AUTOSAR XML (schema 4-2-2)
package /Base_SWC
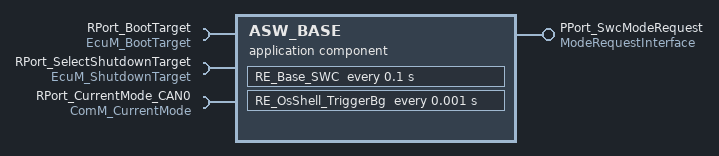
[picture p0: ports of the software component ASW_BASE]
  application sw component type ASW_BASE
    require port RPort_BootTarget: required-interface=EcuM_BootTarget
    require port RPort_SelectShutdownTarget: required-interface=EcuM_ShutdownTarget
    require port RPort_CurrentMode_CAN0: required-interface=ComM_CurrentMode
    provide port PPort_SwcModeRequest: provided-interface=ModeRequestInterface
    behavior IB_Base_SWC: data-type-mapping=[AppMode_Mapping, ComMModeMapping]
      timing event TE_Base_SWC_100ms: start-on-event=RE_Base_SWC, period=0.1
      timing event TE_OsShell_TriggerBg_1ms: start-on-event=RE_OsShell_TriggerBg, period=0.001
      runnable RE_Base_SWC: mode-access-point=RPort_CurrentMode_CAN0.currentMode, symbol=RE_Base_SWC_func
        data-send-points:
          access DSP_AppMode_0: accessed-variable=PPort_SwcModeRequest.AppMode
        7 x sync call:
          SynchronousServerCallPoint_0: operation=RPort_SelectShutdownTarget.GetLastShutdownTarget
          SynchronousServerCallPoint_1: operation=RPort_SelectShutdownTarget.SelectShutdownTarget
          SynchronousServerCallPoint_2: operation=RPort_SelectShutdownTarget.GetShutdownTarget
          SynchronousServerCallPoint_3: operation=RPort_SelectShutdownTarget.SelectShutdownCause
          SynchronousServerCallPoint_4: operation=RPort_SelectShutdownTarget.GetShutdownCause
          SynchronousServerCallPoint_5: operation=RPort_BootTarget.SelectBootTarget
          SynchronousServerCallPoint_6: operation=RPort_BootTarget.GetBootTarget
      runnable RE_OsShell_TriggerBg: symbol=RE_OsShell_TriggerBg_func
